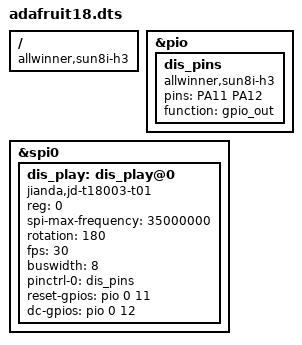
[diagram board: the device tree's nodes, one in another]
/dts-v1/;
/plugin/;

/ {
	compatible = "allwinner,sun8i-h3";

//	fragment@0 {
//		target = <&spi0>;
//		__overlay__ {
//			status = "okay";

			/*spidev@0{
				status = "disabled";
			};*/
//		};
//	};

	fragment@0 {
		target = <&pio>;
		__overlay__ {
			dis_pins: dis_pins {
				compatible = "allwinner,sun8i-h3";
				pins = "PA11 PA12";
				function = "gpio_out";
			};
		};
	};

	fragment@1 {
		target = <&spi0>;
		__overlay__ {
			/* needed to avoid dtc warning */
			#address-cells = <1>;
			#size-cells = <0>;

			dis_play: dis_play@0{
				compatible = "jianda,jd-t18003-t01", "sitronix,st7735r";
				reg = <0>;
                                spi-max-frequency = <35000000>;
				rotation = <180>;
				fps = <30>;
				buswidth = <8>;
				pinctrl-names = "default";
				pinctrl-0 = <&dis_pins>;
				reset-gpios = <&pio 0 11 0>;
				dc-gpios = <&pio 0 12 0>;
//				backlight = <&backlight>;
			};
		};
	};

};
